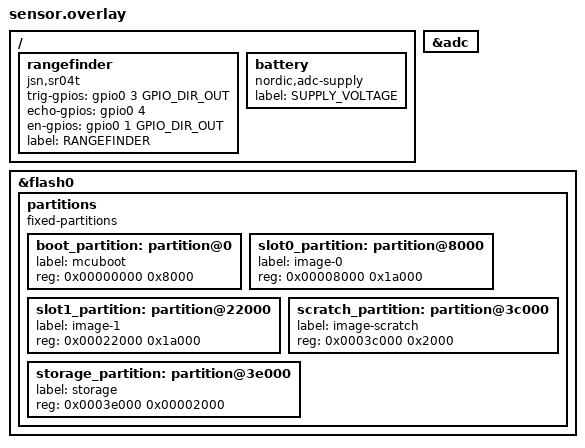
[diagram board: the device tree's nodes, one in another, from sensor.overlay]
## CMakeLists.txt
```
cmake_minimum_required(VERSION 3.13.1)

set(ZEPHYR_TOOLCHAIN_VARIANT gnuarmemb)

set(BOARD nrf51_ble400)
set(CONF_FILE prj.conf)
set(DTC_OVERLAY_FILE ${CMAKE_CURRENT_SOURCE_DIR}/sensor.overlay)

include($ENV{ZEPHYR_BASE}/cmake/app/boilerplate.cmake NO_POLICY_SCOPE)
project(SensorFirmware)

add_subdirectory(src)

# target_link_libraries_ifdef(CONFIG_JSN_SR04T app PUBLIC jsn_sr04t)
```

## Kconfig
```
source "Kconfig.zephyr"

rsource "src/Kconfig"
```

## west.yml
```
west:
  revision: v0.5.8
manifest:
  remotes:
    - name: zephyr
      url-base: https://github.com/zephyrproject-rtos
  projects:
    - name: zephyr
      remote: zephyr
      west-commands: scripts/west-commands.yml
```

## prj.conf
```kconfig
# BLE config
CONFIG_BT=y
CONFIG_BT_PERIPHERAL=y
CONFIG_BT_DEVICE_NAME="Water Level"
CONFIG_BT_DEVICE_APPEARANCE=5184

# BLE security
CONFIG_BT_SMP=y
CONFIG_BT_SMP_SC_ONLY=y
CONFIG_BT_FIXED_PASSKEY=y
CONFIG_BT_DEFAULT_PASSKEY=445693
CONFIG_BT_SETTINGS=y

CONFIG_FLASH=y
CONFIG_FLASH_PAGE_LAYOUT=y
CONFIG_FLASH_MAP=y
CONFIG_FCB=y
CONFIG_SETTINGS=y
CONFIG_SETTINGS_FCB=y

CONFIG_REBOOT=y
CONFIG_GPIO=y
CONFIG_DEVICE_POWER_MANAGEMENT=y
CONFIG_SENSOR=y
CONFIG_JSN_SR04T=y

CONFIG_ADC=y
CONFIG_ADC_0=y
CONFIG_NRFX_ADC_SUPPLY=y

# Debugging
CONFIG_ASSERT=n
CONFIG_BT_DEBUG_LOG=y
```

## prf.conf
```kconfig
# BLE config
CONFIG_BT=y
CONFIG_BT_PERIPHERAL=y
CONFIG_BT_DEVICE_NAME="Water Level"
CONFIG_BT_DEVICE_APPEARANCE=5184

# BLE security
CONFIG_BT_SMP=y
CONFIG_BT_SMP_SC_ONLY=y
CONFIG_BT_FIXED_PASSKEY=y
CONFIG_BT_DEFAULT_PASSKEY=445693
CONFIG_BT_SETTINGS=y

CONFIG_BT_DEBUG_LOG=y

CONFIG_GPIO=y
CONFIG_DEVICE_POWER_MANAGEMENT=y
CONFIG_SENSOR=y
CONFIG_JSN_SR04T=y
CONFIG_JSN_SR04T_EN_GPIO_PIN_NUM=19

CONFIG_FLASH=y
CONFIG_FLASH_PAGE_LAYOUT=y
CONFIG_FLASH_MAP=y
CONFIG_FCB=y
CONFIG_SETTINGS=y
CONFIG_SETTINGS_FCB=y
```

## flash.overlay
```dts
&flash0 {
	/*
	 * For more information, see:
	 * https://docs.zephyrproject.org/latest/guides/dts/index.html#flash-partitions
	 */
	partitions {
		compatible = "fixed-partitions";
		#address-cells = <1>;
		#size-cells = <1>;

		boot_partition: partition@0 {
			label = "mcuboot";
			reg = <0x00000000 0x8000>;
		};
		slot0_partition: partition@8000 {
			label = "image-0";
			reg = <0x00008000 0x1a000>;
		};
		slot1_partition: partition@22000 {
			label = "image-1";
			reg = <0x00022000 0x1a000>;
		};
		scratch_partition: partition@3c000 {
			label = "image-scratch";
			reg = <0x0003c000 0x2000>;
		};
		storage_partition: partition@3e000 {
			label = "storage";
			reg = <0x0003e000 0x00002000>;
		};
	};
};
```

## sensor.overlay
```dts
/ {
    rangefinder: rangefinder {
        status = "ok";
        compatible = "jsn,sr04t";
        trig-gpios = <&gpio0 3 GPIO_DIR_OUT>;
        echo-gpios = <&gpio0 4 (GPIO_DIR_IN | GPIO_INT | GPIO_INT_EDGE | GPIO_INT_DOUBLE_EDGE)>;
        en-gpios = <&gpio0 1 GPIO_DIR_OUT>;
        label = "RANGEFINDER";
    };

    battery: battery {
      status = "ok";
      compatible = "nordic,adc-supply";
      label = "SUPPLY_VOLTAGE";
    };
};

&adc {
    status = "okay";
};

&flash0 {
	/*
	 * For more information, see:
	 * https://docs.zephyrproject.org/latest/guides/dts/index.html#flash-partitions
	 */
	partitions {
		compatible = "fixed-partitions";
		#address-cells = <1>;
		#size-cells = <1>;

		boot_partition: partition@0 {
			label = "mcuboot";
			reg = <0x00000000 0x8000>;
		};
		slot0_partition: partition@8000 {
			label = "image-0";
			reg = <0x00008000 0x1a000>;
		};
		slot1_partition: partition@22000 {
			label = "image-1";
			reg = <0x00022000 0x1a000>;
		};
		scratch_partition: partition@3c000 {
			label = "image-scratch";
			reg = <0x0003c000 0x2000>;
		};
		storage_partition: partition@3e000 {
			label = "storage";
			reg = <0x0003e000 0x00002000>;
		};
	};
};
```

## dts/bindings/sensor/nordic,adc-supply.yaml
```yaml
#
# Copyright (c) 2019, Ben Wolsieffer
#
# SPDX-License-Identifier: GPL-3.0-or-later
#
---
title: NRFx supply voltage sensor
version: 0.1

description: >
  Binding for the NRFx supply voltage sensor
inherits:
  !include base.yaml

properties:
  compatible:
    constraint: "nordic,adc-supply"

...
```

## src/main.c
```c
#include <zephyr.h>
#include <device.h>
#include <gpio.h>
#include <sensor.h>
#include <logging/log.h>
#include <settings/settings.h>
#include "bluetooth.h"
#include "battery.h"
#include "common.h"
#include "temperature.h"

LOG_MODULE_REGISTER(main);

#define LED_PORT LED0_GPIO_CONTROLLER
#define LED LED0_GPIO_PIN

#define SLEEP_TIME 1000

#define NUM_SAMPLES 10

void main(void) {
    int err = 0;
    int cnt = 0;
    struct device* gpio;

    IF_ERR (bluetooth_init()) {
        LOG_ERR("Bluetooth initialization failed (err %d)", err);
    }
    IF_ERR (battery_init()) {
        LOG_ERR("Battery initialization failed (err %d)", err);
    }
    IF_ERR (temperature_init()) {
        LOG_ERR("Temperature initialization failed (err %d)", err);
    }

    gpio = device_get_binding(LED_PORT);
    if (!gpio) {
        LOG_ERR("GPIO initialization failed");
        return;
    }

    // Set LED pin as output
    gpio_pin_configure(gpio, LED, GPIO_DIR_OUT);

    struct device* rangefinder = device_get_binding(DT_JSN_SR04T_RANGEFINDER_LABEL);
    if (!rangefinder) {
        LOG_ERR("Rangefinder initialization failed: %s", DT_JSN_SR04T_RANGEFINDER_LABEL);
        return;
    }

#pragma clang diagnostic push
#pragma clang diagnostic ignored "-Wmissing-noreturn"
    for (;;) {

        temperature_update();

        device_set_power_state(rangefinder, DEVICE_PM_ACTIVE_STATE, NULL, NULL);

        u32_t distance_mm_avg = 0;

        for (int i = 0; i < NUM_SAMPLES;) {
            // Set pin to HIGH/LOW every 1 second
            gpio_pin_write(gpio, LED, cnt % 2);
            ++cnt;

            err = sensor_sample_fetch(rangefinder);
            if (!err) {
                struct sensor_value distance;
                sensor_channel_get(rangefinder, SENSOR_CHAN_DISTANCE, &distance);

                ++i;
                u32_t distance_mm = (u32_t) (distance.val1 * 1000 + distance.val2 / 1000);
                distance_mm_avg += distance_mm;

                printk("Distance: %d mm\n", distance_mm);
            } else {
                LOG_ERR("Failed to get rangefinder (err %d)", err);
            }

            k_sleep(50);
        }

        device_set_power_state(rangefinder, DEVICE_PM_OFF_STATE, NULL, NULL);

        distance_mm_avg /= NUM_SAMPLES;
        printk("Distance (avg): %d mm\n", distance_mm_avg);

        bluetooth_set_water_level((u16_t) distance_mm_avg);

        IF_ERR(battery_update()) {
            LOG_ERR("Failed to update battery (err %d)", err);
        }

        k_sleep(SLEEP_TIME);
    }
#pragma clang diagnostic pop
}
```

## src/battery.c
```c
#include <sensor.h>
#include <adc.h>
#include <logging/log.h>
#include "battery.h"
#include "common.h"
#include "bluetooth.h"

LOG_MODULE_REGISTER(battery);

#define BATTERY_FULL_MILLIVOLTS 3000
#define BATTERY_EMPTY_MILLIVOLTS 1800

static struct device* battery;

int battery_init(void) {
    battery = device_get_binding(DT_NORDIC_ADC_SUPPLY_BATTERY_LABEL);
    if (!battery) return -ENODEV;

    return 0;
}

int battery_update(void) {
    int err = 0;

    RET_ERR(sensor_sample_fetch(battery));

    struct sensor_value voltage;
    RET_ERR(sensor_channel_get(battery, SENSOR_CHAN_VOLTAGE, &voltage));

    u32_t millivolts = (u32_t) (voltage.val1 * 1000 + voltage.val2 / 1000);

    u8_t level = (millivolts - BATTERY_EMPTY_MILLIVOLTS) * 100
                 / (BATTERY_FULL_MILLIVOLTS - BATTERY_EMPTY_MILLIVOLTS);

    level = MIN(level, 100);

    LOG_DBG("Battery state: %d%%, %d.%d V\n", level, voltage.val1, voltage.val2);

    bluetooth_set_battery_level(level);

    return 0;
}
```

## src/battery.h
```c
#pragma once

int battery_init(void);

int battery_update(void);
```

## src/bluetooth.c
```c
#include <bluetooth/bluetooth.h>
#include <bluetooth/conn.h>
#include <bluetooth/uuid.h>
#include <bluetooth/gatt.h>
#include <logging/log.h>
#include <settings/settings.h>
#include "bluetooth.h"
#include "common.h"

LOG_MODULE_REGISTER(bluetooth);

#define BT_CPF_FORMAT_UINT16 0x6

// Water level service (WLS)
#define BT_UUID_WLS_VAL \
    0x01, 0xc7, 0xe3, 0x00, 0xfa, 0xaf, 0x11, 0xe8, \
    0x8b, 0xe5, 0x07, 0x9b, 0x30, 0x95, 0xdd, 0x67

static u8_t battery_level = 87;
static s16_t temperature = 0;
static u16_t water_level = 233;

static void bluetooth_ready(int err);

static ssize_t bluetooth_battery_read(struct bt_conn* conn, const struct bt_gatt_attr* attr,
                                      void* buf, u16_t len, u16_t offset);

static ssize_t bluetooth_temperature_read(struct bt_conn* conn, const struct bt_gatt_attr* attr,
                                          void* buf, u16_t len, u16_t offset);

static ssize_t bluetooth_water_level_read(struct bt_conn* conn, const struct bt_gatt_attr* attr,
                                          void* buf, u16_t len, u16_t offset);

static const struct bt_data ad[] = {
        BT_DATA_BYTES(BT_DATA_FLAGS, (BT_LE_AD_GENERAL | BT_LE_AD_NO_BREDR)),
        BT_DATA_BYTES(BT_DATA_UUID16_ALL,
                      0x0F, 0x18, // Battery Service (0x180F)
                      0x1A, 0x18 // Environmental Sensing Service (0x181A)
        ),
        BT_DATA_BYTES(BT_DATA_UUID128_ALL, BT_UUID_WLS_VAL)
};

static const struct bt_data sd[] = {
        BT_DATA(BT_DATA_NAME_COMPLETE, CONFIG_BT_DEVICE_NAME, sizeof(CONFIG_BT_DEVICE_NAME) - 1)
};

BT_GATT_SERVICE_DEFINE(
        bas_service,
        BT_GATT_PRIMARY_SERVICE(BT_UUID_BAS),
        BT_GATT_CHARACTERISTIC(BT_UUID_BAS_BATTERY_LEVEL,
                               BT_GATT_CHRC_READ,
                               BT_GATT_PERM_READ, bluetooth_battery_read, NULL, NULL),
);

BT_GATT_SERVICE_DEFINE(
        ess_service,
        BT_GATT_PRIMARY_SERVICE(BT_UUID_ESS),
        BT_GATT_CHARACTERISTIC(BT_UUID_TEMPERATURE,
                               BT_GATT_CHRC_READ,
                               BT_GATT_PERM_READ, bluetooth_temperature_read, NULL, NULL),
);

static struct bt_uuid_128 bt_uuid_wls = BT_UUID_INIT_128(BT_UUID_WLS_VAL);

static struct bt_uuid_128 bt_uuid_wls_water_level = BT_UUID_INIT_128(
        0x01, 0xc7, 0xe3, 0x00, 0xfa, 0xaf, 0x11, 0xe8,
        0x8b, 0xe5, 0x07, 0x9b, 0x30, 0x95, 0xdd, 0x67
);

static const struct bt_gatt_cpf wls_water_level_cpf = {
        .format = BT_CPF_FORMAT_UINT16,
        .exponent = -3
};

BT_GATT_SERVICE_DEFINE(
        wls_service,
        BT_GATT_PRIMARY_SERVICE(&bt_uuid_wls),
        BT_GATT_CHARACTERISTIC(&bt_uuid_wls_water_level.uuid,
                               BT_GATT_CHRC_READ,
                               BT_GATT_PERM_READ, bluetooth_water_level_read, NULL, NULL),
        BT_GATT_CPF(&wls_water_level_cpf)
);

static void bluetooth_connected(struct bt_conn *conn, u8_t err) {
    char addr[BT_ADDR_LE_STR_LEN];
    bt_addr_le_to_str(bt_conn_get_dst(conn), addr, sizeof(addr));

    if (err) {
        LOG_ERR("failed to connect to: %s (err %d)", addr, err);
        return;
    }

    LOG_INF("connected to: %s", addr);

    IF_ERR(bt_conn_security(conn, BT_SECURITY_FIPS)) {
        LOG_ERR("failed to enable security (err %d)", err);
    }
}

static struct bt_conn_cb conn_callbacks = {
        .connected = bluetooth_connected,
};

static void bluetooth_passkey_display(struct bt_conn* conn, unsigned int passkey) {
    LOG_INF("passkey: %d\n", passkey);
}

static void bluetooth_auth_cancel(struct bt_conn* conn) {
    char addr[BT_ADDR_LE_STR_LEN];
    bt_addr_le_to_str(bt_conn_get_dst(conn), addr, sizeof(addr));

    LOG_WRN("autentication failed with: %s", addr);
}

static void bluetooth_pairing_complete(struct bt_conn* conn, bool bonded) {
    char addr[BT_ADDR_LE_STR_LEN];
    bt_addr_le_to_str(bt_conn_get_dst(conn), addr, sizeof(addr));

    LOG_INF("paired with: %s\n", addr);
}

static void bluetooth_pairing_failed(struct bt_conn* conn) {
    char addr[BT_ADDR_LE_STR_LEN];
    bt_addr_le_to_str(bt_conn_get_dst(conn), addr, sizeof(addr));

    LOG_WRN("pairing failed with: %s", addr);
    bt_conn_disconnect(conn, BT_HCI_ERR_AUTHENTICATION_FAIL);
}

static struct bt_conn_auth_cb auth_callbacks = {
        .passkey_display = bluetooth_passkey_display,
        .passkey_entry = NULL,
        .passkey_confirm = NULL,
        .cancel = bluetooth_auth_cancel,
        .pairing_complete = bluetooth_pairing_complete,
        .pairing_failed = bluetooth_pairing_failed,
};

static void bluetooth_ready(int err) {
    if (err) {
        LOG_ERR("initialization failed (err %d)\n", err);
        return;
    }

    LOG_DBG("initialized\n");

    // FIXME: why does this need to go here, rather than before bt_enable()?
    IF_ERR(settings_load()) {
        LOG_ERR("failed to load settings (err %d)\n", err);
    }

    IF_ERR(bt_passkey_set(CONFIG_BT_DEFAULT_PASSKEY)) {
        LOG_ERR("setting passkey failed (err %d)\n", err);
    }

    bt_conn_cb_register(&conn_callbacks);
    bt_conn_auth_cb_register(&auth_callbacks);

    err = bt_le_adv_start(BT_LE_ADV_PARAM(
                                  BT_LE_ADV_OPT_CONNECTABLE,
                                  BT_GAP_ADV_SLOW_INT_MIN,
                                  BT_GAP_ADV_SLOW_INT_MAX
                          ), ad, ARRAY_SIZE(ad), sd, ARRAY_SIZE(sd));
    if (err) {
        LOG_ERR("advertising failed to start (err %d)\n", err);
        return;
    }

    LOG_DBG("advertising started\n");
}

static ssize_t bluetooth_battery_read(struct bt_conn* conn, const struct bt_gatt_attr* attr,
                                      void* buf, u16_t len, u16_t offset) {
    return bt_gatt_attr_read(conn, attr, buf, len, offset, &battery_level, sizeof(battery_level));
}

static ssize_t bluetooth_temperature_read(struct bt_conn* conn, const struct bt_gatt_attr* attr,
                                          void* buf, u16_t len, u16_t offset) {
    return bt_gatt_attr_read(conn, attr, buf, len, offset, &temperature, sizeof(temperature));
}

static ssize_t bluetooth_water_level_read(struct bt_conn* conn, const struct bt_gatt_attr* attr,
                                          void* buf, u16_t len, u16_t offset) {
    return bt_gatt_attr_read(conn, attr, buf, len, offset, &water_level, sizeof(water_level));
}

int bluetooth_init(void) {
    int err = 0;

    RET_ERR(bt_enable(bluetooth_ready));

    return err;
}

int bluetooth_set_battery_level(u8_t level) {
    battery_level = level;
    return 0;
}

int bluetooth_set_temperature(s16_t temp) {
    temperature = temp;
    return 0;
}

int bluetooth_set_water_level(u16_t level) {
    water_level = level;
    return 0;
}
```

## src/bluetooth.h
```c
#pragma once

#include <zephyr.h>

enum system_error {
    ERROR_TEMPERATURE = BIT(0),
    ERROR_BATTERY = BIT(1),
    ERROR_WATER_LEVEL = BIT(2)
};

enum system_status {
    STATUS_NEW_DATA = BIT(0),
    STATUS_REBOOT = BIT(1)
};

int bluetooth_init(void);

int bluetooth_set_battery_level(u8_t level);

/**
 * Set the temperature characteristic value.
 *
 * @param temp temperature in milli-celsius
 * @return errno
 */
int bluetooth_set_temperature(s16_t temp);

/**
 * Set a latched error bit.
 *
 * @param e error bit to set
 */
void bluetooth_set_error(enum system_error e);

/**
 * Set the value of a status bit.
 * @param s status bit to set
 * @param value value of the bit
 */
void bluetooth_set_status(enum system_status s, bool value);
```

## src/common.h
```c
#pragma once

#define IF_ERR(s) if ((err = (s)) < 0)

#define RET_ERR(s) IF_ERR(s) return err
```

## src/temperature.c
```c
#include <device.h>
#include <sensor.h>
#include <logging/log.h>
#include "temperature.h"
#include "common.h"
#include "bluetooth.h"

LOG_MODULE_REGISTER(temperature);

static struct device* sensor;

int temperature_init(void) {
    sensor = device_get_binding(CONFIG_TEMP_NRF5_NAME);
    if (!sensor) return -ENODEV;

    return 0;
}

int temperature_update(void) {
    int err = 0;

    RET_ERR(sensor_sample_fetch(sensor));

    struct sensor_value temp;

    RET_ERR(sensor_channel_get(sensor, SENSOR_CHAN_DIE_TEMP, &temp));

    // Temperature in millicelsius
    s32_t temp_mc = temp.val1 * 100 + temp.val2 / 10000;

    temp_mc = MAX(INT16_MIN, MIN(INT16_MAX, temp_mc));

    RET_ERR(bluetooth_set_temperature((s16_t) temp_mc));

    return err;
}
```

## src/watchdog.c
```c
#include <zephyr.h>
#include <logging/log.h>
#include <logging/log_ctrl.h>
#include <misc/reboot.h>

LOG_MODULE_REGISTER(watchdog);

int watchdog_init() {

}

FUNC_NORETURN void _SysFatalErrorHandler(unsigned int reason, const NANO_ESF* pEsf) {
    LOG_ERR("FATAL ERROR... Resetting");
    LOG_PANIC();
    sys_reboot(SYS_REBOOT_COLD);
    CODE_UNREACHABLE;
}
```

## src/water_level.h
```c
#pragma once

int water_level_init(void);

int water_level_update(void);

u16_t water_level_get(void);

u16_t water_level_get_tank_depth(void);

/**
 * Set the depth of the water tank.
 *
 * @param depth depth in millimeters
 */
void water_level_set_tank_depth(u16_t depth);
```
